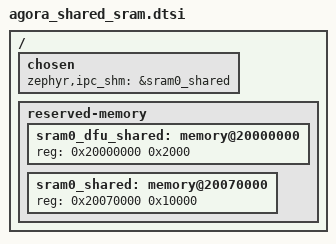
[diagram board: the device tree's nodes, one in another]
/* Default shared SRAM planning when building for nRF5340.
 * This file is included by both nRF5340 CPUAPP (Application MCU)
 * and nRF5340 CPUNET (Network MCU).
 * - 64 kB SRAM allocated as Shared memory (sram0_shared)
 * - Region defined after the image SRAM of Application MCU
 */

/ {
	chosen {
		/* shared memory reserved for the inter-processor communication */
		zephyr,ipc_shm = &sram0_shared;
	};

	reserved-memory {
		#address-cells = <1>;
		#size-cells = <1>;
		ranges;

		/* PCD command block used to hand off the netcore update image
		 * from MCUboot (cpuapp) to b0n (cpunet). See nrf/subsys/pcd.
		 */
		sram0_dfu_shared: memory@20000000 {
			reg = <0x20000000 0x2000>;
		};

		sram0_shared: memory@20070000 {
			/* SRAM allocated to shared memory */
			reg = <0x20070000 0x10000>;
		};
	};
};
